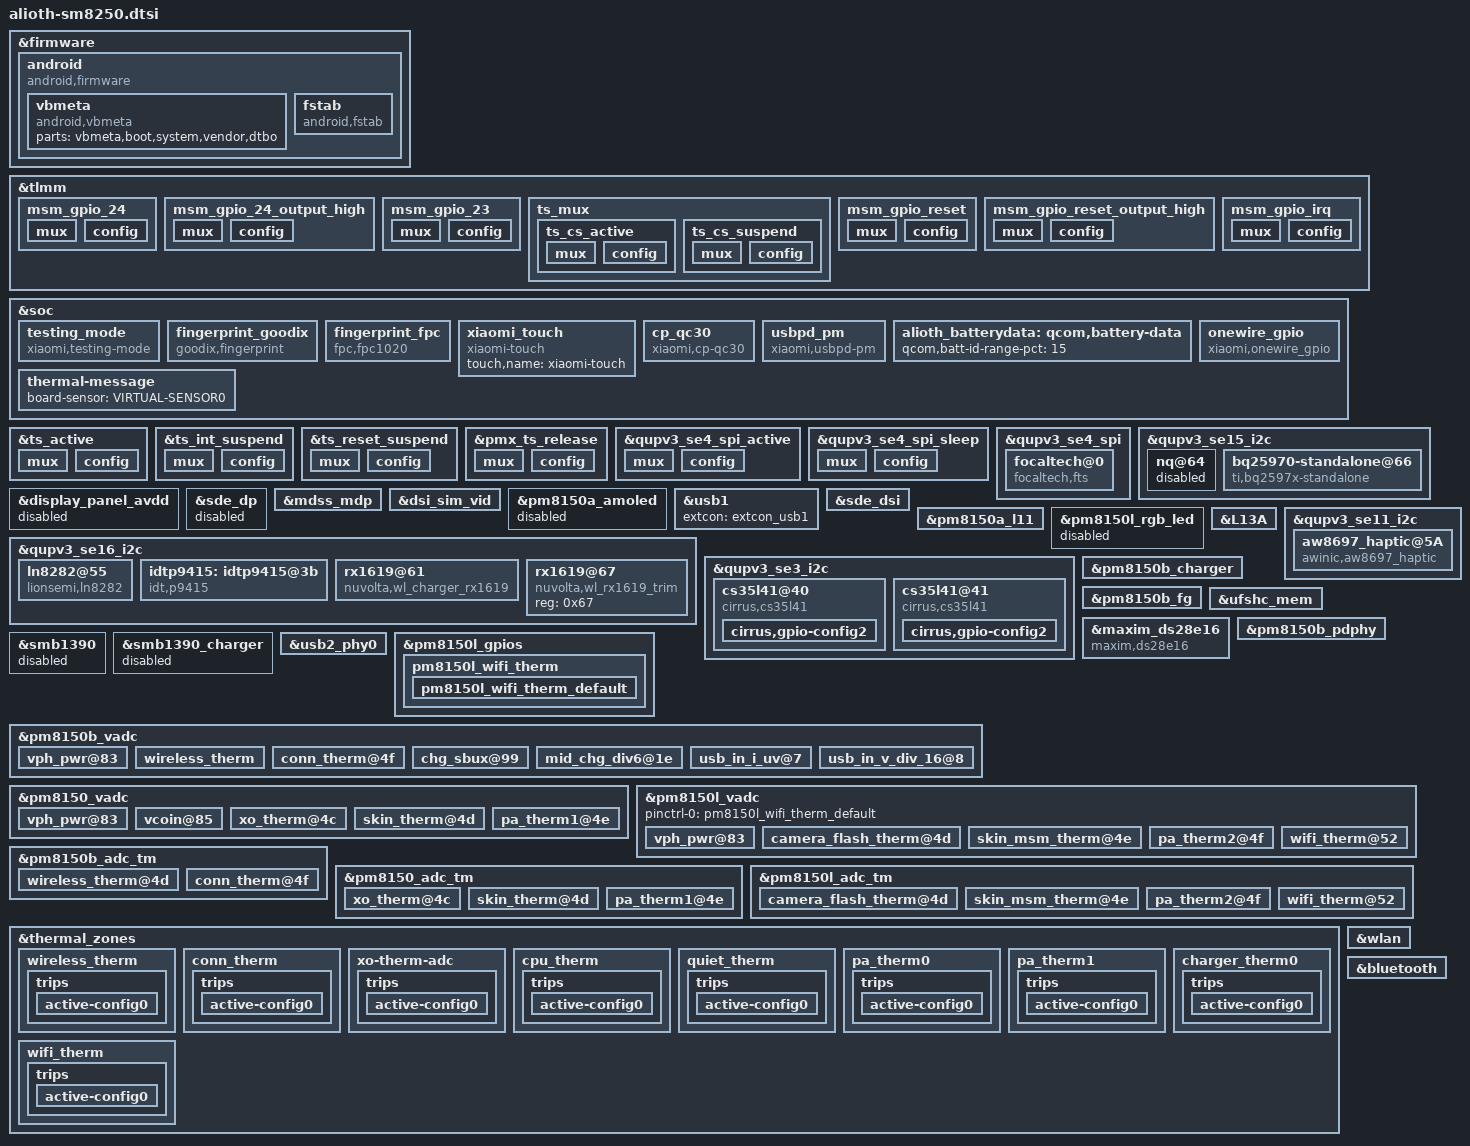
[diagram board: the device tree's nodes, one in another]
/*
this file is for attribution only of alioth
*/

#include "alioth-pinctrl.dtsi"
#include "xiaomi-sm8250-common.dtsi"
#include "alioth-audio-overlay.dtsi"

&firmware {
	android {
		compatible = "android,firmware";
		vbmeta {
			compatible = "android,vbmeta";
			parts = "vbmeta,boot,system,vendor,dtbo";
		};

		fstab {
			compatible = "android,fstab";
		};
	};
};

/*IC int pin, rst pin init*/
&tlmm {
        /* GPIO_24: FP_RESET_N */
        msm_gpio_24: msm_gpio_24 {
                mux {
                         pins = "gpio24";
                         function = "gpio";
                };
                config {
                        pins = "gpio24";
                        drive-strength = <2>;
                        bias-disable;
                        output-low;
                };
        };
        /* GPIO_24 : FP_RESET_N, state device active*/
        msm_gpio_24_output_high: msm_gpio_24_output_high {
                mux {
                        pins = "gpio24";
                        function = "gpio";
                };
                config {
                        pins = "gpio24";
                        drive-strength = <2>;
                        bias-disable;
                        output-high;
                };
        };
        /* GPIO_23 : FP_INT_N */
        msm_gpio_23: msm_gpio_23 {
                mux {
                        pins = "gpio23";
                        function = "gpio";
                };
                config {
                        pins = "gpio23";
                        drive-strength = <2>;
                        bias-pull-down;
                };
        };

};

&soc {

	testing_mode {
		compatible = "xiaomi,testing-mode";
		status-gpio = <&tlmm 70 0x00>;
		debounce-time = <30>;
		pinctrl-names = "default";
		pinctrl-0 = <&test_mode_irq>;
	};

};

&ts_active {
	mux {
		pins = "gpio33", "gpio39";
		function = "gpio";
	};

	config {
		pins = "gpio33", "gpio39";
		drive-strength = <8>;
		bias-pull-up;
	};
};

&ts_int_suspend {
	mux {
		pins = "gpio39";
		function = "gpio";
	};

	config {
		pins = "gpio39";
		drive-strength = <2>;
		bias-pull-down;
	};
};

&ts_reset_suspend {
	mux {
		pins = "gpio33";
		function = "gpio";
	};

	config {
		pins = "gpio33";
		drive-strength = <2>;
		bias-pull-down;
	};
};

&pmx_ts_release {
	mux {
		pins = "gpio33", "gpio39";
		function = "gpio";
	};

	config {
		pins = "gpio33", "gpio39";
		drive-strength = <2>;
		bias-disable;
	};
};
&tlmm {
	ts_mux {
		ts_cs_active: ts_cs_active {
			mux {
				pins = "gpio11";
				function = "qup4";
			};

			config {
				pins = "gpio11";
				drive-strength = <16>;
				bias-pull-up;
			};
		};

		ts_cs_suspend: ts_cs_suspend {
			mux {
				pins = "gpio11";
				function = "gpio";
			};

			config {
				pins = "gpio11";
				drive-strength = <16>;
				bias-pull-up;
			};
		};
	};
};


&qupv3_se4_spi_active {
	mux {
		pins = "gpio8", "gpio9", "gpio10";
		function = "qup4";
	};

	config {
		pins = "gpio8", "gpio9", "gpio10";
		drive-strength = <6>;
		bias-pull-down;
	};
};

&qupv3_se4_spi_sleep {
	mux {
		pins = "gpio8", "gpio9", "gpio10";
		function = "gpio";
	};

	config {
		pins = "gpio8", "gpio9", "gpio10";
		drive-strength = <6>;
		bias-pull-down;
	};
};


&qupv3_se4_spi {
	status = "ok";
	pinctrl-0 = <&qupv3_se4_spi_active &ts_cs_active>;
	pinctrl-1 = <&qupv3_se4_spi_sleep &ts_cs_suspend>;
	focaltech@0 {
		status = "ok";
		compatible = "focaltech,fts";
		reg = <0x0>;
		spi-max-frequency = <10000000>;
		interrupt-parent = <&tlmm>;
		interrupts = <39 0x2008>;
		pinctrl-names = "pmx_ts_active", "pmx_ts_suspend", "pmx_ts_release";
		pinctrl-0 = <&ts_active>;
		pinctrl-1 = <&ts_int_suspend &ts_reset_suspend>;
		pinctrl-2 = <&pmx_ts_release>;
		vdd-supply = <&L10C>;
		vcc_i2c-supply = <&L1C>;
		focaltech,reset-gpio = <&tlmm 33 0x00>;
		focaltech,irq-gpio = <&tlmm 39 0x2008>;
		focaltech,max-touch-number = <10>;
		focaltech,display-coords = <0 0 8640 19200>;
		focaltech,open-min = <3000>;
		focaltech,touch-range-array = <1 5 10 15 20>;
		focaltech,touch-def-array = <3 3 3 3>;
		focaltech,touch-expert-array = <10 10 10 10
						20 20 15 10
						20 20 20 10>;
	};
};

&qupv3_se15_i2c {
	status = "ok";
	nq@64 {
		status = "disabled";
	};
};

&display_panel_avdd {
	status = "disabled";
};

&sde_dp {
	status = "disabled";
};

&mdss_mdp {
	connectors = <&sde_wb &sde_dsi &sde_dsi1 &sde_rscc>;
};

&dsi_sim_vid {
	qcom,panel-supply-entries = <&dsi_panel_pwr_supply_vci>;
	qcom,platform-reset-gpio = <&tlmm 12 0>;
};

&pm8150a_amoled {
	status = "disabled";
};

&usb1 {
        extcon = <&extcon_usb1>;
};

&sde_dsi {
	/delete-property/ vdd-supply;
	/delete-property/ avdd-supply;
	qcom,dsi-default-panel = <&dsi_sim_vid>;
	vci-supply = <&pm8150a_l11>;
};

&pm8150a_l11 {
	qcom,init-voltage = <3000000>;
	regulator-min-microvolt = <3000000>;
	regulator-max-microvolt = <3000000>;
};

&pm8150l_rgb_led {
	status = "disabled";
};

&soc {
	fingerprint_goodix {
		compatible = "goodix,fingerprint";
		goodix,gpio-reset = <&tlmm 24 GPIO_ACTIVE_LOW>;
		goodix,gpio-irq = <&tlmm 23 GPIO_ACTIVE_HIGH>;
		fp_vdd_vreg-supply = <&pm8150_l13>;
		status = "ok";
	};

	fingerprint_fpc {
		status = "ok";
		compatible = "fpc,fpc1020";
		interrupt-parent = <&tlmm>;
		interrupts = <23 0x0>;
		fpc,gpio_rst    = <&tlmm 24 0x0>;
		fpc,gpio_irq    = <&tlmm 23 0x0>;
		fp_vdd_vreg-supply = <&L13A>;
		pinctrl-names = "fpc1020_reset_reset",
			"fpc1020_reset_active",
			"fpc1020_irq_active";

		pinctrl-0 = <&msm_gpio_24>;
		pinctrl-1 = <&msm_gpio_24_output_high>;
		pinctrl-2 = <&msm_gpio_23>;

	};

/*
	fingerprint_3P0_VREG: fingerprint_3P0_VREG {
		compatible = "regulator-fixed";
		regulator-name = "fingerprint_3P0_VREG";
		startup-delay-us = <4000>;
		enable-active-high;
		gpio = <&tlmm 10 0>;
		regulator-always-on;
	};
*/
	xiaomi_touch {
		compatible = "xiaomi-touch";
		status = "ok";
		touch,name = "xiaomi-touch";
	};

};

&L13A {
	regulator-min-microvolt = <3304000>;
	regulator-max-microvolt = <3304000>;
	qcom,init-voltage = <3304000>;
};

&tlmm {
		/* FP_RESET_N */
	msm_gpio_reset: msm_gpio_reset {
		mux {
			pins = "gpio24";
			function = "gpio";
		};
		config {
			pins = "gpio24";
			drive-strength = <2>;
			bias-disable;
			output-low;
		};
	};
		/* FP_RESET_N, state device active*/
	msm_gpio_reset_output_high: msm_gpio_reset_output_high {
		mux {
			pins = "gpio24";
			function = "gpio";
		};
		config {
			pins = "gpio24";
			drive-strength = <2>;
			bias-disable;
			output-high;
		};
	};
		/* FP_INT_N */
	msm_gpio_irq: msm_gpio_irq {
		mux {
			pins = "gpio23";
			function = "gpio";
		};
		config {
			pins = "gpio23";
			drive-strength = <2>;
			bias-pull-down;
		};
	};
};

&qupv3_se15_i2c {
	#address-cells = <1>;
	#size-cells = <0>;
	status = "ok";
	bq25970-standalone@66 {
		compatible = "ti,bq2597x-standalone";
		reg = <0x66>;
		interrupt-parent = <&tlmm>;
		interrupts = <68 0x2002>;
		pinctrl-names = "default";
		pinctrl-0 = <&bq2597x_master_int_default>;

		/*ti,bq2597x,bat-ovp-disable;*/
		ti,bq2597x,bat-ovp-alarm-disable;
		ti,bq2597x,bat-ocp-disable;
		ti,bq2597x,bat-ocp-alarm-disable;
		ti,bq2597x,bat-ucp-alarm-disable;
		ti,bq2597x,bat-ucp-disable;

		/*ti,bq2597x,bus-ovp-alarm-disable;
		ti,bq2597x,bus-ocp-disable;
		ti,bq2597x,bus-ocp-alarm-disable;*/
		ti,bq2597x,bat-therm-disable;
		ti,bq2597x,bus-therm-disable;
		ti,bq2597x,die-therm-disable;

		ti,bq2597x,bat-ovp-threshold = <4525>;
		ti,bq2597x,bat-ovp-alarm-threshold = <4525>;
		//ti,bq2597x,bat-ocp-threshold = <8000>;
		//ti,bq2597x,bat-ocp-alarm-threshold = <7500>;

		ti,bq2597x,bus-ovp-threshold = <12000>;
		ti,bq2597x,bus-ovp-alarm-threshold = <11000>;
		ti,bq2597x,bus-ocp-threshold = <3750>;
		ti,bq2597x,bus-ocp-alarm-threshold = <3500>;

		//ti,bq2597x,bat-ucp-alarm-threshold = <2000>;

		ti,bq2597x,bat-therm-threshold = <0x15>;/*4.1%*/
		ti,bq2597x,bus-therm-threshold = <0x15>;/*4.1%*/
		ti,bq2597x,die-therm-threshold = <145>;

		ti,bq2597x,ac-ovp-threshold = <14>;
		//ti,bq2597x,sense-resistor-mohm = <2>;
	};
};

&qupv3_se16_i2c {
	status = "ok";
	ln8282@55 {
		compatible = "lionsemi,ln8282";
		status = "ok";
		reg = <0x55>;
		ln,enable = <&tlmm 156 0x00>;
		ln,irq = <&tlmm 158 0x00>;
		pinctrl-names = "ln8282_active","ln8282_suspend";
		pinctrl-0 = <&ln8282_enable_active>;
		pinctrl-1 = <&ln8282_enable_suspend>;
	};

	idtp9415: idtp9415@3b {
		compatible = "idt,p9415";
		status = "ok";
		reg = <0x3b>;
		idt,irq = <&tlmm 157 0x00>;
		idt,enable = <&tlmm 155 0x00>;
		idt,reverse-enable = <&tlmm 154 0x00>;
		idt,wpc-det = <&pm8150b_gpios 7 GPIO_ACTIVE_HIGH>;
		pinctrl-names = "default", "idt_active", "idt_suspend";
		pinctrl-0 = <&power_good_default>;
		pinctrl-1 = <&idt_int_active &idt_enable_active &txon_enable_active>;
		pinctrl-2 = <&idt_int_suspend &idt_enable_suspend &txon_enable_suspend>;
		mi,wireless-by-usbin;
		mi,only-idt-on-cmi;
	};

	rx1619@61 {
		compatible = "nuvolta,wl_charger_rx1619";
		reg = <0x61>;
		status = "ok";
		rx,irq_gpio = <&tlmm 157 0x00>;
		rx,tx_on_gpio = <&tlmm 154 0x00>;
		rx,power_good = <&pm8150b_gpios 7 GPIO_ACTIVE_HIGH>;
		rx,enable = <&tlmm 155 0x00>;
		pinctrl-names = "default","nu_active","nu_suspend";
		pinctrl-0 = <&power_good_default>;
		pinctrl-1 = <&nu_int_active &txon_enable_active &nu_sleep_active>;
		pinctrl-2 = <&nu_int_suspend &txon_enable_suspend &nu_sleep_suspend>;
		mi,wireless-by-usbin;
	};

	rx1619@67 {
		compatible = "nuvolta,wl_rx1619_trim";
		reg = <0x67>;
		status = "ok";
	};
};

&qupv3_se3_i2c {
	status = "ok";

        /* Speaker */
	cs35l41@40 {
		#sound-dai-cells = <1>;
		compatible = "cirrus,cs35l41";
		reset-gpios = <&tlmm 114 0>;
		reg = <0x40>;
		pinctrl-names = "cs35l41_irq_speaker";
		pinctrl-0 = <&cs35l41_int_speaker>;
		interrupt-parent = <&tlmm>;
		interrupts = <113 8>;
		cirrus,temp-warn_threshold = <3>;
		cirrus,boost-peak-milliamp = <4000>;
		cirrus,boost-ind-nanohenry = <1000>;
		cirrus,boost-cap-microfarad = <15>;
		cirrus,asp-sdout-hiz = <3>;
		//cirrus,right-channel-amp;
		sound-name-prefix = "RCV";
		cirrus,gpio-config2 {
			cirrus,gpio-src-select = <0x4>;
			cirrus,gpio-output-enable;
		};

	};
	/* Receiver */
	cs35l41@41 {
		#sound-dai-cells = <1>;
		compatible = "cirrus,cs35l41";
		reset-gpios = <&tlmm 114 0>;
		reg = <0x41>;
		pinctrl-names = "cs35l41_irq_speaker_rcv";
		pinctrl-0 = <&cs35l41_int_speaker_rcv>;
		interrupt-parent = <&tlmm>;
		interrupts = <112 8>;
		cirrus,temp-warn_threshold = <3>;
		cirrus,boost-peak-milliamp = <4000>;
		cirrus,boost-ind-nanohenry = <1000>;
		cirrus,boost-cap-microfarad = <15>;
		cirrus,right-channel-amp;
		cirrus,asp-sdout-hiz = <3>;
		//sound-name-prefix = "RCV";
		cirrus,gpio-config2 {
			cirrus,gpio-src-select = <0x4>;
			cirrus,gpio-output-enable;
		};

	};

};

&qupv3_se11_i2c {
	status = "ok";
	aw8697_haptic@5A {
		compatible = "awinic,aw8697_haptic";
		vib_bst_vol_default = < 0x11 >;
		vib_bst_vol_ram = < 0x11 >;
		vib_bst_vol_rtp = < 0x11 >;
		status = "ok";
	};
};
&pm8150b_charger {
	status = "ok";
	qcom,sec-charger-config = <0>;
	qcom,usb-icl-ua = <3000000>;
	qcom,fcc-max-ua = <6000000>;
	qcom,fv-max-uv = <4460000>;
	qcom,non-fcc-fv-max-uv = <4450000>;
	qcom,dc-icl-ua = <1000000>;
	qcom,auto-recharge-soc = <99>;
	qcom,chg-term-src = <1>;
	qcom,chg-term-current-ma = <(-220)>;
	//qcom,step-charging-enable;
	qcom,sw-jeita-enable;
	qcom,chg-warm-th= <480>;
	qcom,chg-cool-th= <150>;
	//qcom,suspend-input-on-debug-batt;
	qcom,usbpd-phandle = <&pm8150b_pdphy>;
	qcom,battery-data = <&alioth_batterydata>;
	mi,six-pin-step-chg-params = <4250000  6000000
				4450000  5400000
				4460000  3536000>;
	mi,six-pin-step-chg;
	mi,six-pin-soc-th = <22>;
	mi,fcc-batt-unverify-ua = <2000000>;
	mi,support-ffc;
	qcom,lpd-disable;
	mi,use-bq-pump;
	mi,chg-enable-k11a;
	mi,support-second-ffc-term-current;
	mi,support-second-ffc-term-current-diff = <133>;
	mi,support-qc3p5-without-smb;
	qcom,disable-suspend-on-collapse;
	qcom,distinguish-qc-class-ab;
//	qcom,support-conn-therm;
//	vbus-disable-gpio = <&tlmm 6 GPIO_ACTIVE_HIGH>;
//	pinctrl-names = "default", "vbus_disable_active", "vbus_disable_suspend";
//	pinctrl-0 = <&vbus_disable_suspend>;
//	pinctrl-1 = <&vbus_disable_active>;
//	pinctrl-2 = <&vbus_disable_suspend>;

	io-channels = <&pm8150b_vadc ADC_USB_IN_V_16>,
			<&pm8150b_vadc ADC_MID_CHG_DIV6>,
			<&pm8150b_vadc ADC_USB_IN_I>,
			<&pm8150b_vadc ADC_SBUx>,
			<&pm8150b_vadc ADC_VPH_PWR>,
			<&pm8150b_vadc ADC_AMUX_THM3_PU2>,
			<&pm8150b_vadc ADC_CHG_TEMP>;
	io-channel-names = "usb_in_voltage",
			"mid_voltage",
			"usb_in_current",
			"sbux_res",
			"vph_voltage",
			"conn_temp",
			"chg_temp";
	qcom,thermal-mitigation = <3000000 2800000 2600000 2400000 2200000 2100000 2000000
				   1800000 1600000 1500000 1400000 1200000 1000000 900000
				   800000 500000>;
	qcom,thermal-mitigation-icl
				= <2800000 2700000 2600000 2400000 2200000 2100000 2000000
				   1800000 1600000 1500000 1400000 1300000 1200000 1100000
				   950000 750000>;
	qcom,thermal-mitigation-dcp
				= <1800000 1800000 1800000 1800000 1800000 1800000 1800000
				   1800000 1800000 1700000 1600000 1400000 1200000 1100000
				   1100000 1000000>;
	qcom,thermal-mitigation-qc2
				= <1500000 1500000 1500000 1500000 1450000 1400000 1350000
				   1300000 1150000 1100000 1000000 900000 850000 750000
				   650000 500000>;
	qcom,thermal-fcc-qc3-normal
				= <3200000 3000000 2800000 2600000 2500000 2400000 2300000
				   2200000 2100000 1800000 1600000 1400000 1200000 1000000
				   750000 750000>;
	qcom,thermal-fcc-qc3-cp
				= <4800000 4600000 4400000 4200000 4000000 3800000 3600000
				   3400000 3000000 2600000 2400000 2200000 2000000 1300000
				   1000000 700000>;
	qcom,thermal-fcc-qc3-classb-cp
				= <5100000 4700000 4300000 4000000 3600000 3500000 3400000
				   3400000 3400000 3200000 2500000 2200000 2000000 700000
				   300000 100000>;
	qcom,thermal-mitigation-pd-base
				= <3000000 2800000 2600000 2400000 2200000 2000000 1800000
				   1600000 1600000 1400000 1200000 1100000 1050000 1000000
				   950000 500000>;
	qcom,thermal-fcc-pps-bq
				= <6000000 5400000 5000000 4400000 4000000 3700000 3500000
				   3000000 2800000 2500000 2000000 1500000 1000000 700000
				   300000 100000>;
};

&pm8150b_fg {
	qcom,battery-data = <&alioth_batterydata>;
	qcom,rapid-soc-dec-en;
	qcom,five-pin-battery;
	qcom,soc-hi-res;
	qcom,sun-profile-only;
	qcom,k11a-batt-profile;
	qcom,soc_decimal_rate = <
		0  38
		10 35
		20 33
		30 33
		40 33
		50 33
		60 33
		70 30
		80 25
		90 20
		95 10 >;
	qcom,fg-sys-term-current = <(-300)>;
	qcom,fg-ffc-sys-term-current = <(-1300)>;
	qcom,ki-coeff-low-chg = <315>;
	qcom,ki-coeff-med-chg = <183>;
	qcom,fg-cutoff-voltage = <3400>;
	qcom,fg-cutoff-voltage-global = <3400>;
	qcom,fg-cutoff-current = <200>;
	qcom,fg-empty-voltage = <3100>;
	qcom,fg-batt-temp-hyst = <1>;
	qcom,fg-batt-temp-delta = <6>;
	qcom,soc-scale-vbatt-mv = <3600>;
	qcom,fg-force-load-profile;
	qcom,ki-coeff-chg-med-hi-thresh-ma = <1000>;
	qcom,ki-coeff-chg-low-med-thresh-ma = <500>;
	qcom,ffc-ki-coeff-chg-med-hi-thresh-ma = <3900>;
	qcom,ffc-ki-coeff-chg-low-med-thresh-ma = <3500>;
	//qcom,fg-increase-100soc-time;
	qcom,fg-increase-100soc-time-2;
	qcom,shutdown-delay-enable;
};

&soc {
	cp_qc30 {
		compatible = "xiaomi,cp-qc30";
		status = "ok";
		mi,qc3-bat-volt-max = <4420>;
		mi,qc3-bat-curr-max = <3600>;
		mi,qc3-bus-volt-max = <12000>;
		mi,qc3-bus-curr-max = <2100>;
		mi,qc3-battery-warm-th = <480>;
		mi,use-qcom-gauge;
		mi,support-qc3p5-without-smb;
		//mi,cp-sec-enable;
	};

	usbpd_pm {
		compatible = "xiaomi,usbpd-pm";
		status = "ok";
		mi,pd-bat-volt-max = <4460>;
		mi,pd-bat-curr-max = <6000>;
		mi,pd-bus-volt-max = <12000>;
		mi,pd-bus-curr-max = <3000>;
		mi,pd-bus-curr-compensate  = <50>;
		mi,pd-non-ffc-bat-volt-max = <4450>;
		mi,pd-battery-warm-th = <480>;
		mi,use-qcom-gauge;
		//mi,cp-sec-enable;
		mi,therm-level-threshold = <12>;
		mi,chg-enable-k11a;
		mi,pd-power-max = <33>; /*charge power max : 33W */
	};

	alioth_batterydata: qcom,battery-data {
		qcom,batt-id-range-pct = <15>;
		#include "fg-gen4-batterydata-alioth-FMT-4520mah.dtsi"
		#include "fg-gen4-batterydata-alioth-GY-4520mah.dtsi"
	};

	onewire_gpio: onewire_gpio {
		compatible = "xiaomi,onewire_gpio";
		label = "xm_onewire";
		xiaomi,version = <1>;
		xiaomi,ow_gpio = <&tlmm 25 0x00>;
		mi,onewire-gpio-cfg-addr = <0x0F519000 0x4>;
		xiaomi,gpio_number = <25>;
		pinctrl-names = "onewire_active", "onewire_sleep";
		pinctrl-0 = <&onewire_gpio_active>;
		pinctrl-1 = <&onewire_gpio_sleep>;
		status = "ok";
	};
};

&ufshc_mem {
	vccq_set_npm = /bits/ 16 <0x1AD>;

	hsg4_synclength = /bits/ 16 <0x145 0x4F
				     0x1AD 0x4F
				     0x12C 0x4F>;

	status = "ok";
};

&maxim_ds28e16 {
	compatible = "maxim,ds28e16";
	label = "max_ds28e16";
	maxim,version = <1>;
	status = "ok";
	mi,factory-enable;
};

&pm8150b_pdphy {
	mi,non-qcom-pps-ctrl;
	mi,pd-power-max = <33>; /*charge power max : 33W */
};

&smb1390 {
	status = "disabled";
};

&smb1390_charger {
	status = "disabled";
};

&usb2_phy0 {
	qcom,param-override-seq =
		<0xE5 0x6C
		 0xfa 0x70
		 0x2c 0x74>;
	qcom,global-param-override-seq =
		<0xE5 0x6C
		 0xfa 0x70
		 0x2c 0x74>;
};

&pm8150l_gpios {
	pm8150l_wifi_therm {
		pm8150l_wifi_therm_default: pm8150l_wifi_therm_default {
			pins = "gpio5";
			bias-high-impedance;
		};
	};
};

&pm8150b_vadc {
	#address-cells = <1>;
	#size-cells = <0>;

	vph_pwr@83 {
		reg = <ADC_VPH_PWR>;
		label = "vph_pwr";
		qcom,pre-scaling = <1 3>;
	};

	wireless_therm {
		reg = <ADC_AMUX_THM1_PU2>;
		label = "wireless_therm";
		qcom,ratiometric;
		qcom,hw-settle-time = <200>;
		qcom,pre-scaling = <1 1>;
	};

	conn_therm@4f {
		reg = <ADC_AMUX_THM3_PU2>;
		label = "conn_therm";
		qcom,ratiometric;
		qcom,hw-settle-time = <200>;
		qcom,pre-scaling = <1 1>;
	};

	chg_sbux@99 {
		reg = <ADC_SBUx>;
		label = "chg_sbux";
		qcom,pre-scaling = <1 3>;
	};

	mid_chg_div6@1e {
		reg = <ADC_MID_CHG_DIV6>;
		label = "chg_mid";
		qcom,pre-scaling = <1 6>;
	};

	usb_in_i_uv@7 {
		reg = <ADC_USB_IN_I>;
		label = "usb_in_i_uv";
		qcom,pre-scaling = <1 1>;
	};

	usb_in_v_div_16@8 {
		reg = <ADC_USB_IN_V_16>;
		label = "usb_in_v_div_16";
		qcom,pre-scaling = <1 16>;
	};
};

&pm8150_vadc {
	#address-cells = <1>;
	#size-cells = <0>;

	vph_pwr@83 {
		reg = <ADC_VPH_PWR>;
		label = "vph_pwr";
		qcom,pre-scaling = <1 3>;
	};

	vcoin@85 {
		reg = <ADC_VCOIN>;
		label = "vcoin";
		qcom,pre-scaling = <1 3>;
	};

	xo_therm@4c {
		reg = <ADC_XO_THERM_PU2>;
		label = "xo_therm";
		qcom,ratiometric;
		qcom,hw-settle-time = <200>;
		qcom,pre-scaling = <1 1>;
	};

	skin_therm@4d {
		reg = <ADC_AMUX_THM1_PU2>;
		label = "skin_therm";
		qcom,ratiometric;
		qcom,hw-settle-time = <200>;
		qcom,pre-scaling = <1 1>;
	};

	pa_therm1@4e {
		reg = <ADC_AMUX_THM2_PU2>;
		label = "pa_therm1";
		qcom,ratiometric;
		qcom,hw-settle-time = <200>;
		qcom,pre-scaling = <1 1>;
	};
};

&pm8150l_vadc {
	#address-cells = <1>;
	#size-cells = <0>;
	pinctrl-0 = <&pm8150l_wifi_therm_default>;

	vph_pwr@83 {
		reg = <ADC_VPH_PWR>;
		label = "vph_pwr";
		qcom,pre-scaling = <1 3>;
	};

	camera_flash_therm@4d {
		reg = <ADC_AMUX_THM1_PU2>;
		label = "camera_flash_therm";
		qcom,ratiometric;
		qcom,hw-settle-time = <200>;
		qcom,pre-scaling = <1 1>;
	};

	skin_msm_therm@4e {
		reg = <ADC_AMUX_THM2_PU2>;
		label = "skin_msm_therm";
		qcom,ratiometric;
		qcom,hw-settle-time = <200>;
		qcom,pre-scaling = <1 1>;
	};

	pa_therm2@4f {
		reg = <ADC_AMUX_THM3_PU2>;
		label = "pa_therm2";
		qcom,ratiometric;
		qcom,hw-settle-time = <200>;
		qcom,pre-scaling = <1 1>;
	};

	wifi_therm@52 {
		reg = <ADC_GPIO1_PU2>;
		label = "wifi_therm";
		qcom,ratiometric;
		qcom,hw-settle-time = <200>;
		qcom,pre-scaling = <1 1>;
	};
};

&pm8150b_adc_tm {
	#address-cells = <1>;
	#size-cells = <0>;

	io-channels = <&pm8150b_vadc ADC_AMUX_THM1_PU2>,
			<&pm8150b_vadc ADC_AMUX_THM3_PU2>;

	wireless_therm@4d {
		reg = <ADC_AMUX_THM1_PU2>;
		qcom,ratiometric;
		qcom,hw-settle-time = <200>;
	};

	conn_therm@4f {
		reg = <ADC_AMUX_THM3_PU2>;
		qcom,ratiometric;
		qcom,hw-settle-time = <200>;
	};
};

&pm8150_adc_tm {
	#address-cells = <1>;
	#size-cells = <0>;

	io-channels = <&pm8150_vadc ADC_XO_THERM_PU2>,
			<&pm8150_vadc ADC_AMUX_THM1_PU2>,
			<&pm8150_vadc ADC_AMUX_THM2_PU2>;

	xo_therm@4c {
		reg = <ADC_XO_THERM_PU2>;
		qcom,ratiometric;
		qcom,hw-settle-time = <200>;
	};

	skin_therm@4d {
		reg = <ADC_AMUX_THM1_PU2>;
		qcom,ratiometric;
		qcom,hw-settle-time = <200>;
	};

	pa_therm1@4e {
		reg = <ADC_AMUX_THM2_PU2>;
		qcom,ratiometric;
		qcom,hw-settle-time = <200>;
	};
};

&pm8150l_adc_tm {
	#address-cells = <1>;
	#size-cells = <0>;

	io-channels = <&pm8150l_vadc ADC_AMUX_THM1_PU2>,
			<&pm8150l_vadc ADC_AMUX_THM2_PU2>,
			<&pm8150l_vadc ADC_AMUX_THM3_PU2>,
			<&pm8150l_vadc ADC_GPIO1_PU2>;

	camera_flash_therm@4d {
		reg = <ADC_AMUX_THM1_PU2>;
		qcom,ratiometric;
		qcom,hw-settle-time = <200>;
	};

	skin_msm_therm@4e {
		reg = <ADC_AMUX_THM2_PU2>;
		qcom,ratiometric;
		qcom,hw-settle-time = <200>;
	};

	pa_therm2@4f {
		reg = <ADC_AMUX_THM3_PU2>;
		qcom,ratiometric;
		qcom,hw-settle-time = <200>;
	};

	wifi_therm@52 {
		reg = <ADC_GPIO1_PU2>;
		qcom,ratiometric;
		qcom,hw-settle-time = <200>;
	};
};

&thermal_zones {
	wireless_therm {//place close to wireless charge RX
		polling-delay-passive = <0>;
		polling-delay = <0>;
		thermal-governor = "user_space";
		thermal-sensors = <&pm8150b_adc_tm ADC_AMUX_THM1_PU2>;
		trips {
			active-config0 {
				temperature = <125000>;
				hysteresis = <1000>;
				type = "passive";
			};
		};
	};

	conn_therm {//place close to type-c connector
		polling-delay-passive = <0>;
		polling-delay = <0>;
		thermal-governor = "user_space";
		thermal-sensors = <&pm8150b_adc_tm ADC_AMUX_THM3_PU2>;
		wake-capable-sensor;
		trips {
			active-config0 {
				temperature = <125000>;
				hysteresis = <1000>;
				type = "passive";
			};
		};
	};

	xo-therm-adc {
		polling-delay-passive = <0>;
		polling-delay = <0>;
		thermal-governor = "user_space";
		thermal-sensors = <&pm8150_adc_tm ADC_XO_THERM_PU2>;
		wake-capable-sensor;
		trips {
			active-config0 {
				temperature = <125000>;
				hysteresis = <1000>;
				type = "passive";
			};
		};
	};

	cpu_therm {//place close to sm8250
		polling-delay-passive = <0>;
		polling-delay = <0>;
		thermal-governor = "user_space";
		thermal-sensors = <&pm8150_adc_tm ADC_AMUX_THM1_PU2>;
		wake-capable-sensor;
		trips {
			active-config0 {
				temperature = <125000>;
				hysteresis = <1000>;
				type = "passive";
			};
		};
	};

	quiet_therm {//place close to cool place
		polling-delay-passive = <0>;
		polling-delay = <0>;
		thermal-governor = "user_space";
		thermal-sensors = <&pm8150_adc_tm ADC_AMUX_THM2_PU2>;
		wake-capable-sensor;
		trips {
			active-config0 {
				temperature = <125000>;
				hysteresis = <1000>;
				type = "passive";
			};
		};
	};

	pa_therm0 {//place close to pa0
		polling-delay-passive = <0>;
		polling-delay = <0>;
		thermal-governor = "user_space";
		thermal-sensors = <&pm8150l_adc_tm ADC_AMUX_THM1_PU2>;
		wake-capable-sensor;
		trips {
			active-config0 {
				temperature = <125000>;
				hysteresis = <1000>;
				type = "passive";
			};
		};
	};

	pa_therm1 {//place close to pa1
		polling-delay-passive = <0>;
		polling-delay = <0>;
		thermal-governor = "user_space";
		thermal-sensors = <&pm8150l_adc_tm ADC_AMUX_THM2_PU2>;
		wake-capable-sensor;
		trips {
			active-config0 {
				temperature = <125000>;
				hysteresis = <1000>;
				type = "passive";
			};
		};
	};

	charger_therm0 {//place close to charge IC
		polling-delay-passive = <0>;
		polling-delay = <0>;
		thermal-governor = "user_space";
		thermal-sensors = <&pm8150l_adc_tm ADC_AMUX_THM3_PU2>;
		wake-capable-sensor;
		trips {
			active-config0 {
				temperature = <125000>;
				hysteresis = <1000>;
				type = "passive";
			};
		};
	};

	wifi_therm {//place close to wifi
		polling-delay-passive = <0>;
		polling-delay = <0>;
		thermal-governor = "user_space";
		thermal-sensors = <&pm8150l_adc_tm ADC_GPIO1_PU2>;
		wake-capable-sensor;
		trips {
			active-config0 {
				temperature = <125000>;
				hysteresis = <1000>;
				type = "passive";
			};
		};
	};
};

&wlan {
       vdd-wlan-dig-supply = <&pm8150_s6>;
       qcom,vdd-wlan-dig-config = <950000 950000 0 0 1>;
};

&bluetooth {
        qca,bt-vdd-dig-supply = <&pm8150_s6>;
        qca,bt-vdd-dig-voltage-level = <950000 950000>;
};

&soc {
	thermal-message {
		board-sensor = "VIRTUAL-SENSOR0";
	};
};
